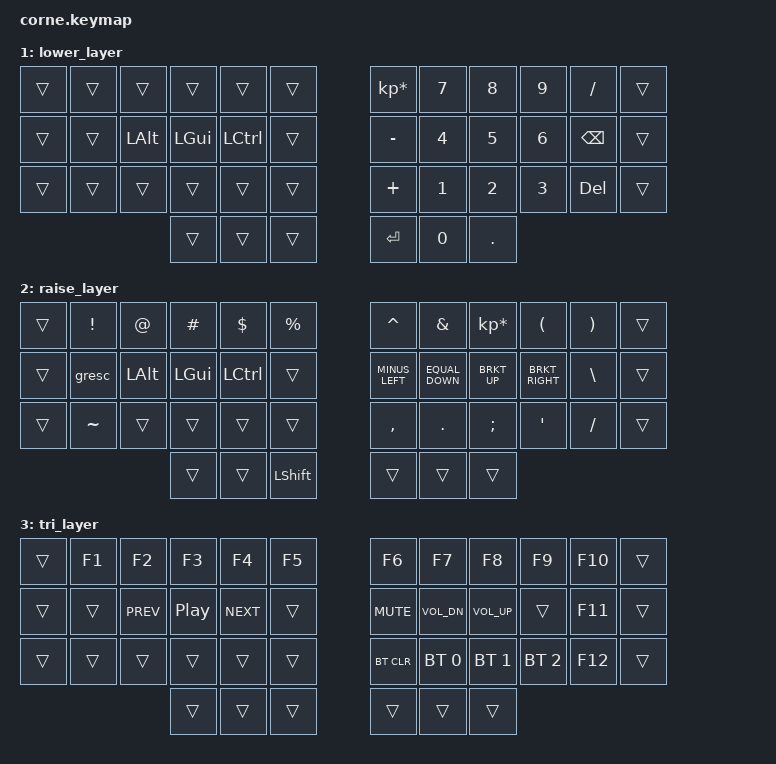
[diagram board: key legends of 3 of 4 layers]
/*
 * Copyright (c) 2020 The ZMK Contributors
 *
 * SPDX-License-Identifier: MIT
 */

#include <behaviors.dtsi>
#include <dt-bindings/zmk/keys.h>
#include <dt-bindings/zmk/bt.h>
#include <dt-bindings/zmk/outputs.h>

#define HRML(k2,k3,k4) &ht LALT k2 &ht LGUI k3 &ht LCTRL k4
#define HRMR(k1,k2,k3) &ht RCTRL k1 &ht RGUI k2 &ht RALT k3

#define BAS 0
#define LEF 1
#define RIG 2
#define TRI 3

/ {
        behaviors {
            ht: hold_tap {
                label = "hold_tap";
                compatible = "zmk,behavior-hold-tap";
                #binding-cells = <2>;
                flavor = "tap-preferred";
                tapping-term-ms = <220>;
                quick-tap-ms = <150>;
                global-quick-tap;
                bindings = <&kp>, <&kp>;
            };
            MINUS_LEFT: MINUS_LEFT {
                compatible = "zmk,behavior-mod-morph";
                label = "MINUS_LEFT";
                #binding-cells = <0>;
                bindings = <&kp MINUS>, <&kp LEFT>;
                mods = <(MOD_LALT|MOD_LCTL|MOD_RALT|MOD_RCTL)>;
            };
            EQUAL_DOWN: EQUAL_DOWN {
                compatible = "zmk,behavior-mod-morph";
                label = "EQUAL_DOWN";
                #binding-cells = <0>;
                bindings = <&kp EQUAL>, <&kp DOWN>;
                mods = <(MOD_LALT|MOD_LCTL|MOD_RALT|MOD_RCTL)>;
            };
            BRKT_UP: BRKT_UP {
                compatible = "zmk,behavior-mod-morph";
                label = "BRKT_UP";
                #binding-cells = <0>;
                bindings = <&kp LBKT>, <&kp UP>;
                mods = <(MOD_LALT|MOD_LCTL|MOD_RALT|MOD_RCTL)>;
            };
            BRKT_RIGHT: BRKT_RIGHT {
                compatible = "zmk,behavior-mod-morph";
                label = "BRKT_RIGHT";
                #binding-cells = <0>;
                bindings = <&kp RBKT>, <&kp RIGHT>;
                mods = <(MOD_LALT|MOD_LCTL|MOD_RALT|MOD_RCTL)>;
            };                         
        };

        conditional_layers {
            compatible = "zmk,conditional-layers";
            tri_layer {
                if-layers = <RIG LEF>;
                then-layer = <TRI>;
            };
        };

        keymap {
                compatible = "zmk,keymap";
                default_layer {
                    bindings = <
                        //╭──────────┬──────────┬──────────┬──────────┬──────────┬──────────╮   ╭──────────┬──────────┬──────────┬──────────┬──────────┬──────────╮
                        //│          │  Q       │  W       │  E       │  R       │  T       │   │  Y       │  U       │  I       │  O       │  P       │          │
                            &trans     &kp Q      &kp W      &kp E      &kp R      &kp T          &kp Y      &kp U      &kp I      &kp O      &kp P      &trans
                        //├──────────┼──────────┼──────────┼──────────┼──────────┼──────────┤   ├──────────┼──────────┼──────────┼──────────┼──────────┼──────────┤
                        //│          │  A       │  S       │  D       │  F       │  G       │   │  H       │  J       │  K       │  L       │ BKSP     │          │
                            &trans     &kp A     HRML(S,         D,         F)       &kp G        &kp H    HRMR(J,         K,         L)      &kp BSPC  &trans
                        //├──────────┼──────────┼──────────┼──────────┼──────────┼──────────┤   ├──────────┼──────────┼──────────┼──────────┼──────────┤──────────┤
                        //│          │  Z       │  X       │  C       │  V       │  B       │   │  N       │  M       │ , <      │ . >      │ DEL      │          │
                            &trans     &kp Z     &kp X       &kp C      &kp V      &kp B          &kp N      &kp M      &kp COMMA  &kp DOT    &kp DEL    &trans
                        //╰──────────┴──────────┴──────────┴──────────┼──────────┼──────────┤   ├──────────┼──────────┼──────────┴──────────┴──────────┴──────────╯
                        //                                 │  GUI     │  LWR     │ SHFT ENT │   │  SPC     │ RSE      │ TAB      │
                                                            &kp LGUI  &mo LEF &mt LSHFT RET     &kp SPC  &mo RIG  &kp TAB
                        //                                 ╰──────────┴──────────┴──────────╯   ╰──────────┴──────────┴──────────╯
                    >;
                };

                lower_layer {
                    bindings = <
                        //╭──────────┬──────────┬──────────┬──────────┬──────────┬──────────╮   ╭──────────┬──────────┬──────────┬──────────┬──────────┬──────────╮
                        //│          │          │          │          │          │          │   │    *     │  7       │  8       │  9       │  /       │          │
                            &trans     &trans     &trans    &trans     &trans     &trans         &kp KP_MULTIPLY &kp N7   &kp N8   &kp N9  &kp FSLH      &trans
                        //├──────────┼──────────┼──────────┼──────────┼──────────┼──────────┤   ├──────────┼──────────┼──────────┼──────────┼──────────┼──────────┤
                        //│          │          │          │          │          │          │   │    -     │  4       │  5       │  6       │ BKSP     │          │
                            &trans     &trans     &kp LALT  &kp LGUI   &kp LCTRL  &trans          &kp MINUS  &kp N4     &kp N5     &kp N6     &kp BSPC   &trans
                        //├──────────┼──────────┼──────────┼──────────┼──────────┼──────────┤   ├──────────┼──────────┼──────────┼──────────┼──────────┤──────────┤
                        //│          │          │          │          │          │          │   │    +     │  1       │  2       │  3       │ DEL      │          │
                            &trans     &trans     &trans    &trans     &trans    &trans         &kp PLUS   &kp N1     &kp N2     &kp N3     &kp DEL    &trans
                        //╰──────────┴──────────┴──────────┴──────────┼──────────┼──────────┤   ├──────────┼──────────┼──────────┴──────────┴──────────┴──────────╯
                        //                                 │          │          │          │   │   ENT    │   0      │  .       │
                                                            &trans     &trans     &trans        &kp RET    &kp N0     &kp DOT
                        //                                 ╰──────────┴──────────┴──────────╯   ╰──────────┴──────────┴──────────╯
                    >;
                };

                raise_layer {
                    bindings = <
                        //╭──────────┬──────────┬──────────┬──────────┬──────────┬──────────╮   ╭──────────┬──────────┬──────────┬──────────┬──────────┬──────────╮
                        //│          │  !       │  @       │ #        │  $       │  %       │   │  ^       │  &       │  *       │  (       │  )       │          │
                            &trans    &kp EXCL   &kp AT    &kp HASH   &kp DLLR   &kp PRCNT      &kp CARET  &kp AMPS   &kp KP_MULTIPLY &kp LPAR &kp RPAR  &trans
                        //├──────────┼──────────┼──────────┼──────────┼──────────┼──────────┤   ├──────────┼──────────┼──────────┼──────────┼──────────┼──────────┤
                        //│          │  `       │          │          │          │          │   │  - _     │  = +     │  [ {     │  } ]     │  \ "|"   │          │
                            &trans    &gresc     &kp LALT  &kp LGUI   &kp LCTRL    &trans          &MINUS_LEFT   &EQUAL_DOWN     &BRKT_UP     &BRKT_RIGHT &kp BSLH   &trans 
                        //├──────────┼──────────┼──────────┼──────────┼──────────┼──────────┤   ├──────────┼──────────┼──────────┼──────────┼──────────┤──────────┤
                        //│          │  ~       │          │          │          │          │   │  , <     │  . >     │  : ;     │  ' "     │ / ?      │          │
                            &trans    &kp TILDE  &trans      &trans     &trans     &trans         &kp COMMA  &kp DOT   &kp SEMI   &kp SQT   &kp FSLH    &trans
                        //╰──────────┴──────────┴──────────┴──────────┼──────────┼──────────┤   ├──────────┼──────────┼──────────┴──────────┴──────────┴──────────╯
                        //                                 │          │          │ SHFT     │   │          │          │          │
                                                            &trans   &trans      &kp LSHFT        &trans    &trans     &trans
                        //                                 ╰──────────┴──────────┴──────────╯   ╰──────────┴──────────┴──────────╯
                    >;
                };

                tri_layer {
                    bindings = <
                        //╭──────────┬──────────┬──────────┬──────────┬──────────┬──────────╮   ╭──────────┬──────────┬──────────┬──────────┬──────────┬──────────╮
                        //│          │   F1     │  F2      │  F3      │  F4      │  F5      │   │  F6      │  F7      │  F8      │  F9      │ F10      │          │
                            &trans     &kp F1     &kp F2    &kp F3     &kp F4     &kp F5         &kp F6     &kp F7     &kp F8     &kp F9     &kp F10    &trans
                        //├──────────┼──────────┼──────────┼──────────┼──────────┼──────────┤   ├──────────┼──────────┼──────────┼──────────┼──────────┼──────────┤
                        //│          │          │  PREV    │  PAUSE   │  NEXT    │          │   │  MUTE    │ VOL DOWN │ VOL UP   │          │ F11      │          │
                            &trans     &trans   &kp C_PREV  &kp C_PP  &kp C_NEXT  &trans       &kp C_MUTE &kp C_VOL_DN &kp C_VOL_UP  &trans  &kp F11  &trans
                        //├──────────┼──────────┼──────────┼──────────┼──────────┼──────────┤   ├──────────┼──────────┼──────────┼──────────┼──────────┤──────────┤
                        //│          │          │          │          │          │          │   │  BT CLR  │  BT 0    │ BT 1     │  BT 2    │ F12      │          │
                            &trans      &trans  &trans      &trans    &trans      &trans      &bt BT_CLR &bt BT_SEL 0 &bt BT_SEL 1 &bt BT_SEL 2 &kp F12   &trans
                        //╰──────────┴──────────┴──────────┴──────────┼──────────┼──────────┤   ├──────────┼──────────┼──────────┴──────────┴──────────┴──────────╯
                        //                                 │          │          │          │   │          │          │          │
                                                             &trans     &trans    &trans         &trans    &trans     &trans
                        //                                 ╰──────────┴──────────┴──────────╯   ╰──────────┴──────────┴──────────╯
                    >;
                };
        };
};
